VERSION ""

NS_ :

BS_:

BU_: PECC SECC
VAL_TABLE_ chargeModeType 3 "dynamicBpt" 2 "dynamic" 1 "scheduled" 0 "unknown" ;
VAL_TABLE_ evConnectionStateType 3 "error" 2 "energyTransferAllowed" 1 "connected" 0 "disconnected" ;
VAL_TABLE_ operationalStatusType 1 "inoperative" 0 "operative" ;
VAL_TABLE_ isolationStatusType 3 "fault" 2 "warning" 1 "valid" 0 "invalid" ;
VAL_TABLE_ contactorsStatusType 1 "closed" 0 "open" ;
VAL_TABLE_ chargingStateType 4 "postCharge" 3 "charge" 2 "preCharge" 1 "cableCheck" 0 "standby" ;

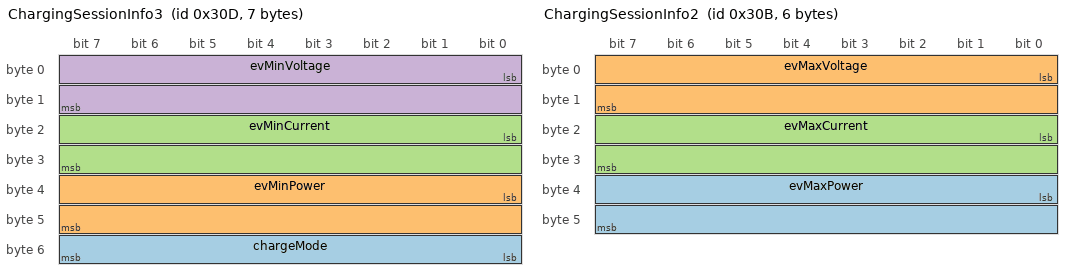
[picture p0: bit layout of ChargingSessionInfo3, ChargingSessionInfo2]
BO_ 781 ChargingSessionInfo3: 7 SECC
 SG_ chargeMode : 48|8@1- (1,0) [0|0] ""  PECC
 SG_ evMinPower : 32|16@1+ (10,0) [0|655350] "W"  PECC
 SG_ evMinCurrent : 16|16@1+ (0.1,0) [0|6553.5] "A"  PECC
 SG_ evMinVoltage : 0|16@1+ (1,0) [0|65535] "V"  PECC

BO_ 779 ChargingSessionInfo2: 6 SECC
 SG_ evMaxPower : 32|16@1+ (1000,0) [0|65535000] "W"  PECC
 SG_ evMaxVoltage : 0|16@1+ (1,0) [0|65535] "V"  PECC
 SG_ evMaxCurrent : 16|16@1+ (1,0) [0|65535] "A"  PECC

BO_ 778 ChargingSessionInfo1: 4 SECC
 SG_ timeToFullSoc : 16|16@1+ (1,0) [0|65535] "s"  PECC
 SG_ chargingProfileMaxPowerLimit : 0|16@1+ (10,0) [0|655350] "W"  PECC

BO_ 777 StopCharging: 0 PECC

BO_ 776 VehicleId: 6 SECC
 SG_ vehicleId : 0|48@1- (1,0) [0|0] ""  PECC

BO_ 773 PECCLimits2: 4 PECC
 SG_ limitCurrentMin : 0|16@1- (0.1,0) [-3276.8|3276.7] "A"  SECC
 SG_ limitCurrentMax : 16|16@1- (0.1,0) [-3276.8|3276.7] "A"  SECC

BO_ 771 PECCStatus2: 6 PECC
 SG_ measuredCurrent : 16|16@1- (0.1,0) [-3276.8|3276.7] "A"  SECC
 SG_ measuredVoltage : 0|16@1+ (0.1,0) [0|6553.5] "V"  SECC

BO_ 774 Reset: 0 SECC

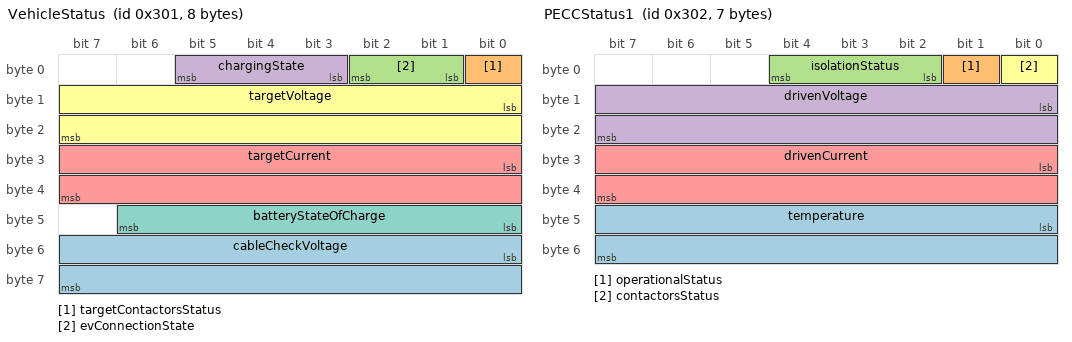
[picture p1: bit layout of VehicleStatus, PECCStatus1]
BO_ 769 VehicleStatus: 8 SECC
 SG_ cableCheckVoltage : 48|16@1+ (1,0) [0|65535] "V"  PECC
 SG_ targetContactorsStatus : 0|1@1+ (1,0) [0|1] ""  PECC
 SG_ evConnectionState : 1|2@1+ (1,0) [0|3] ""  PECC
 SG_ chargingState : 3|3@1+ (1,0) [0|7] ""  PECC
 SG_ targetCurrent : 24|16@1- (0.1,0) [-3276.8|3276.7] "A"  PECC
 SG_ targetVoltage : 8|16@1+ (0.1,0) [0|6553.5] "V"  PECC
 SG_ batteryStateOfCharge : 40|7@1+ (1,0) [0|100] "%"  PECC

BO_ 770 PECCStatus1: 7 PECC
 SG_ temperature : 40|16@1- (0.1,0) [-3276.8|3276.7] "°C"  SECC
 SG_ operationalStatus : 1|1@1+ (1,0) [0|1] ""  SECC
 SG_ isolationStatus : 2|3@1+ (1,0) [0|7] ""  SECC
 SG_ drivenVoltage : 8|16@1+ (0.1,0) [0|6553.5] "V"  SECC
 SG_ drivenCurrent : 24|16@1- (0.1,0) [-3276.8|3276.7] "A"  SECC
 SG_ contactorsStatus : 0|1@1+ (1,0) [0|1] ""  SECC

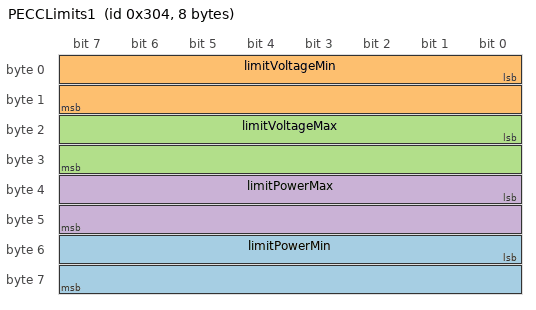
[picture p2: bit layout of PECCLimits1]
BO_ 772 PECCLimits1: 8 PECC
 SG_ limitPowerMin : 48|16@1+ (10,0) [0|655350] "W"  SECC
 SG_ limitVoltageMin : 0|16@1+ (0.1,0) [0|6553.5] "V"  SECC
 SG_ limitVoltageMax : 16|16@1+ (0.1,0) [0|6553.5] "V"  SECC
 SG_ limitPowerMax : 32|16@1+ (10,0) [0|655350] "W"  SECC

BA_DEF_ SG_  "GenSigSendType" ENUM  "Cyclic","OnWrite","OnWriteWithRepetition","OnChange","OnChangeWithRepetition","IfActive","IfActiveWithRepetition","NoSigSendType","NotUsed","NotUsed","NotUsed","NotUsed","NotUsed";
BA_DEF_ BO_  "GenMsgSendType" ENUM  "Cyclic","NotUsed","NotUsed","NotUsed","NotUsed","NotUsed","NotUsed","IfActive","NoMsgSendType","NotUsed","vector_leerstring";
BA_DEF_ BO_  "GenMsgCycleTime" INT 0 50000;
BA_DEF_ BO_  "GenMsgILSupport" ENUM  "No","Yes";
BA_DEF_ BU_  "NodeLayerModules" STRING ;
BA_DEF_  "NmBaseAddress" HEX 1024 1087;
BA_DEF_  "BusType" STRING ;
BA_DEF_DEF_  "GenSigSendType" "Cyclic";
BA_DEF_DEF_  "GenMsgSendType" "NoMsgSendType";
BA_DEF_DEF_  "GenMsgCycleTime" 0;
BA_DEF_DEF_  "GenMsgILSupport" "Yes";
BA_DEF_DEF_  "NodeLayerModules" "CANoeILNLVector.dll";
BA_DEF_DEF_  "NmBaseAddress" 1024;
BA_DEF_DEF_  "BusType" "CAN";
BA_ "GenMsgCycleTime" BO_ 781 250;
BA_ "GenMsgSendType" BO_ 781 0;
BA_ "GenMsgSendType" BO_ 779 0;
BA_ "GenMsgCycleTime" BO_ 779 250;
BA_ "GenMsgSendType" BO_ 778 0;
BA_ "GenMsgCycleTime" BO_ 778 250;
BA_ "GenMsgSendType" BO_ 773 0;
BA_ "GenMsgCycleTime" BO_ 773 250;
BA_ "GenMsgSendType" BO_ 771 0;
BA_ "GenMsgCycleTime" BO_ 771 250;
BA_ "GenMsgCycleTime" BO_ 769 250;
BA_ "GenMsgSendType" BO_ 769 0;
BA_ "GenMsgCycleTime" BO_ 770 250;
BA_ "GenMsgSendType" BO_ 770 0;
BA_ "GenMsgCycleTime" BO_ 772 250;
BA_ "GenMsgSendType" BO_ 772 0;
VAL_ 781 chargeMode 3 "dynamicBpt" 2 "dynamic" 1 "scheduled" 0 "unknown" ;
VAL_ 769 targetContactorsStatus 1 "closed" 0 "open" ;
VAL_ 769 evConnectionState 3 "error" 2 "energyTransferAllowed" 1 "connected" 0 "disconnected" ;
VAL_ 769 chargingState 4 "postCharge" 3 "charge" 2 "preCharge" 1 "cableCheck" 0 "standby" ;
VAL_ 770 operationalStatus 1 "inoperative" 0 "operative" ;
VAL_ 770 isolationStatus 3 "fault" 2 "warning" 1 "valid" 0 "invalid" ;
VAL_ 770 contactorsStatus 1 "closed" 0 "open" ;
